VERSION ""
NS_ :

BS_:

BU_: BMS DCM DIM FSM GSM PDM DEBUG

BO_ 102 BMS_Test1: 1 BMS
SG_ Ex1 : 0|1@1+ (1,0) [0|1] "" DEBUG

BO_ 100 BMS_Alerts: 0 BMS

BO_ 202 DCM_Test1: 1 DCM
SG_ Ex1 : 0|1@1+ (1,0) [0|1] "" DEBUG

BO_ 200 DCM_Alerts: 0 DCM

BO_ 502 DIM_Vitals: 1 DIM
SG_ Heartbeat : 0|1@1+ (1,0) [0|1] "" DEBUG
SG_ State : 1|1@1+ (1,0) [0|0] "" DEBUG

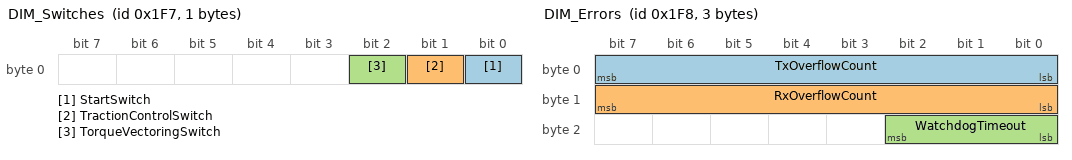
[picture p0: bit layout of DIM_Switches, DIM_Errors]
BO_ 503 DIM_Switches: 1 DIM
SG_ StartSwitch : 0|1@1+ (1,0) [0|1] "" DEBUG
SG_ TractionControlSwitch : 1|1@1+ (1,0) [0|1] "" DEBUG
SG_ TorqueVectoringSwitch : 2|1@1+ (1,0) [0|1] "" DEBUG

BO_ 504 DIM_Errors: 3 DIM
SG_ TxOverflowCount : 0|8@1+ (1,0) [0|255] "" DEBUG
SG_ RxOverflowCount : 8|8@1+ (1,0) [0|255] "" DEBUG
SG_ WatchdogTimeout : 16|3@1+ (1,0) [0|4] "" DEBUG

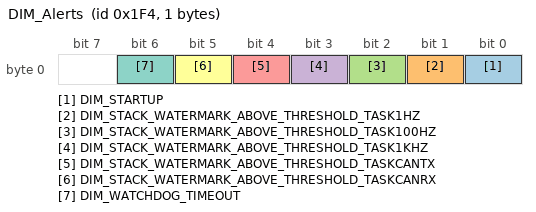
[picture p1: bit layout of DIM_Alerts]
BO_ 500 DIM_Alerts: 1 DIM
SG_ DIM_STARTUP : 0|1@1+ (1,0) [0|1] "" DEBUG
SG_ DIM_STACK_WATERMARK_ABOVE_THRESHOLD_TASK1HZ : 1|1@1+ (1,0) [0|1] "" DEBUG
SG_ DIM_STACK_WATERMARK_ABOVE_THRESHOLD_TASK100HZ : 2|1@1+ (1,0) [0|1] "" DEBUG
SG_ DIM_STACK_WATERMARK_ABOVE_THRESHOLD_TASK1KHZ : 3|1@1+ (1,0) [0|1] "" DEBUG
SG_ DIM_STACK_WATERMARK_ABOVE_THRESHOLD_TASKCANTX : 4|1@1+ (1,0) [0|1] "" DEBUG
SG_ DIM_STACK_WATERMARK_ABOVE_THRESHOLD_TASKCANRX : 5|1@1+ (1,0) [0|1] "" DEBUG
SG_ DIM_WATCHDOG_TIMEOUT : 6|1@1+ (1,0) [0|1] "" DEBUG

BO_ 303 FSM_Test1: 1 FSM
SG_ Ex1 : 0|1@1+ (1,0) [0|1] "" DEBUG

BO_ 300 FSM_Alerts: 0 FSM

BO_ 603 GSM_Test1: 1 GSM
SG_ Ex1 : 0|1@1+ (1,0) [0|1] "" DEBUG

BO_ 600 GSM_Alerts: 0 GSM

BO_ 403 PDM_Test1: 1 PDM
SG_ Ex1 : 0|1@1+ (1,0) [0|1] "" DEBUG

BO_ 400 PDM_Alerts: 0 PDM

BA_DEF_  "BusType" STRING ;
BA_DEF_DEF_  "BusType" "CAN";

BA_ "GenSigStartValue" SG_ 102 Ex1 0;
BA_ "GenSigStartValue" SG_ 202 Ex1 0;
BA_ "GenSigStartValue" SG_ 502 Heartbeat 0;
BA_ "GenSigStartValue" SG_ 502 State 0;
BA_ "GenSigStartValue" SG_ 503 StartSwitch 0;
BA_ "GenSigStartValue" SG_ 503 TractionControlSwitch 0;
BA_ "GenSigStartValue" SG_ 503 TorqueVectoringSwitch 0;
BA_ "GenSigStartValue" SG_ 504 TxOverflowCount 0;
BA_ "GenSigStartValue" SG_ 504 RxOverflowCount 0;
BA_ "GenSigStartValue" SG_ 504 WatchdogTimeout 0;
BA_ "GenSigStartValue" SG_ 500 DIM_STARTUP 0;
BA_ "GenSigStartValue" SG_ 500 DIM_STACK_WATERMARK_ABOVE_THRESHOLD_TASK1HZ 0;
BA_ "GenSigStartValue" SG_ 500 DIM_STACK_WATERMARK_ABOVE_THRESHOLD_TASK100HZ 0;
BA_ "GenSigStartValue" SG_ 500 DIM_STACK_WATERMARK_ABOVE_THRESHOLD_TASK1KHZ 0;
BA_ "GenSigStartValue" SG_ 500 DIM_STACK_WATERMARK_ABOVE_THRESHOLD_TASKCANTX 0;
BA_ "GenSigStartValue" SG_ 500 DIM_STACK_WATERMARK_ABOVE_THRESHOLD_TASKCANRX 0;
BA_ "GenSigStartValue" SG_ 500 DIM_WATCHDOG_TIMEOUT 0;
BA_ "GenSigStartValue" SG_ 303 Ex1 0;
BA_ "GenSigStartValue" SG_ 603 Ex1 0;
BA_ "GenSigStartValue" SG_ 403 Ex1 0;

BA_ "GenMsgCycleTime" BO_ 102  1000;
BA_ "GenMsgCycleTime" BO_ 202  1000;
BA_ "GenMsgCycleTime" BO_ 502  1000;
BA_ "GenMsgCycleTime" BO_ 503  1000;
BA_ "GenMsgCycleTime" BO_ 504  1000;
BA_ "GenMsgCycleTime" BO_ 303  1000;
BA_ "GenMsgCycleTime" BO_ 603  1000;
BA_ "GenMsgCycleTime" BO_ 403  1000;

VAL_ 502 State 0 "DIM_STATE_DRIVE";
VAL_ 503 StartSwitch 0 "SWITCH_ON" 1 "SWITCH_OFF";
VAL_ 503 TractionControlSwitch 0 "SWITCH_ON" 1 "SWITCH_OFF";
VAL_ 503 TorqueVectoringSwitch 0 "SWITCH_ON" 1 "SWITCH_OFF";
VAL_ 504 WatchdogTimeout 0 "RTOS_TASK_1HZ" 1 "RTOS_TASK_100HZ" 2 "RTOS_TASK_1KHZ" 3 "RTOS_TASK_CAN_TX" 4 "RTOS_TASK_CAN_RX";
